# DA1469x register map
Vendor: Dialog; Series: DA1469x; File version: 1.2
CPU: CM33 r1p0, little endian, no MPU, FPU, 3 interrupt priority bits
Registers are 32-bit, read-write, reset 0x0 unless marked. A register's access mark holds for its fields unless they carry their own. Offsets are from the block's base; [hi:lo] are bit positions.

## RTC — RTC registers
Base 0x50000400
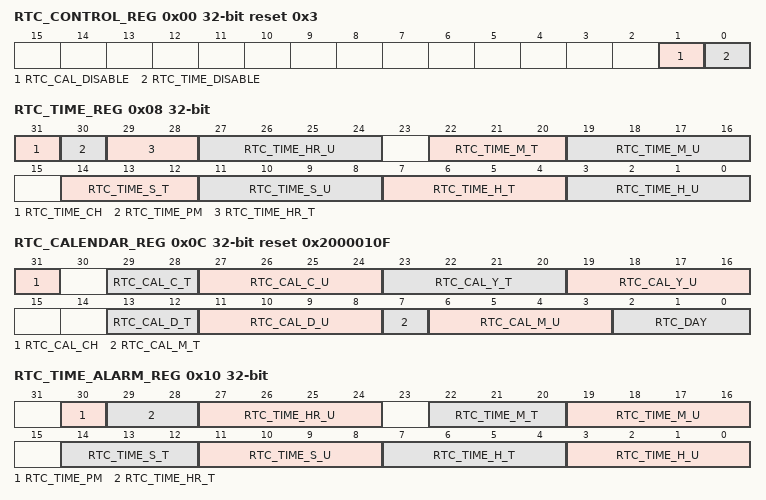
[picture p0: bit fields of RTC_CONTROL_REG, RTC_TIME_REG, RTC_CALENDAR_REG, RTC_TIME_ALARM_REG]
0x00 RTC_CONTROL_REG reset 0x3 — RTC Control Register
  [1] RTC_CAL_DISABLE — When this field is set high the RTC stops incrementing the calendar value.
  [0] RTC_TIME_DISABLE — When this field is set high the RTC stops incrementing the time value.
0x04 RTC_HOUR_MODE_REG — RTC Hour Mode Register
  [0] RTC_HMS — When this field is set high the RTC operates in 12 hour clock mode; otherwise, times are in 24 hour clock format.
0x08 RTC_TIME_REG (reset mask 0x7FFFFFFF) — RTC Time Register
  [31] RTC_TIME_CH — The value in this register has altered since last read. Read and clear.
  [30] RTC_TIME_PM — In 12 hour clock mode, indicates PM when set.
  [29:28] RTC_TIME_HR_T — Hours tens. Represented in BCD digit (0-2).
  [27:24] RTC_TIME_HR_U — Hours units. Represented in BCD digit (0-9).
  [22:20] RTC_TIME_M_T — Minutes tens. Represented in BCD digit (0-5).
  [19:16] RTC_TIME_M_U — Minutes units. Represented in BCD digit (0-9).
  [14:12] RTC_TIME_S_T — Seconds tens. Represented in BCD digit (0-9).
  [11:8] RTC_TIME_S_U — Seconds units. Represented in BCD digit (0-9).
  [7:4] RTC_TIME_H_T — Hundredths of a second tens. Represented in BCD digit (0-9).
  [3:0] RTC_TIME_H_U — Hundredths of a second units. Represented in BCD digit (0-9).
0x0C RTC_CALENDAR_REG reset 0x2000010F (reset mask 0x7FFFFFFF) — RTC Calendar Register
  [31] RTC_CAL_CH — The value in this register has altered since last read. Read and clear
  [29:28] RTC_CAL_C_T — Century tens. Represented in BCD digit (1-2).
  [27:24] RTC_CAL_C_U — Century units. Represented in BCD digit (0-9).
  [23:20] RTC_CAL_Y_T — Year tens. Represented in BCD digit (0-9).
  [19:16] RTC_CAL_Y_U — Year units. Represented in BCD digit (0-9).
  [13:12] RTC_CAL_D_T — Date tens. Represented in BCD digit (0-3).
  [11:8] RTC_CAL_D_U — Date units. Represented in BCD digit (0-9).
  [7] RTC_CAL_M_T — Month tens. Represented in BCD digit (0-1).
  [6:3] RTC_CAL_M_U — Month units. Represented in BCD digit (0-9).
  [2:0] RTC_DAY — Day of the week (arbitrary) units. Represented in BCD digit (0-7).
0x10 RTC_TIME_ALARM_REG — RTC Time Alarm Register
  [30] RTC_TIME_PM — In 12 hour clock mode, indicates PM when set.
  [29:28] RTC_TIME_HR_T — Hours tens. Represented in BCD digit (0-2).
  [27:24] RTC_TIME_HR_U — Hours units. Represented in BCD digit (0-9).
  [22:20] RTC_TIME_M_T — Minutes tens. Represented in BCD digit (0-5).
  [19:16] RTC_TIME_M_U — Minutes units. Represented in BCD digit (0-9).
  [14:12] RTC_TIME_S_T — Seconds tens. Represented in BCD digit (0-9).
  [11:8] RTC_TIME_S_U — Seconds units. Represented in BCD digit (0-9).
  [7:4] RTC_TIME_H_T — Hundredths of a second tens. Represented in BCD digit (0-9).
  [3:0] RTC_TIME_H_U — Hundredths of a second units. Represented in BCD digit (0-9).
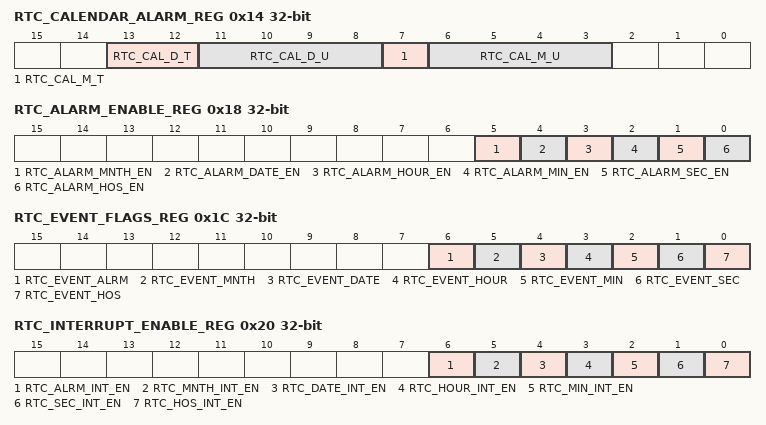
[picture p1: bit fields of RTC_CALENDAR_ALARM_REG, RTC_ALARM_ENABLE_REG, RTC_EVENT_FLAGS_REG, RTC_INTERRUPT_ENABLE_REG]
0x14 RTC_CALENDAR_ALARM_REG — RTC Calendar Alram Register
  [13:12] RTC_CAL_D_T — Date tens. Represented in BCD digit (0-3).
  [11:8] RTC_CAL_D_U — Date units. Represented in BCD digit (0-9).
  [7] RTC_CAL_M_T — Month tens. Represented in BCD digit (0-1).
  [6:3] RTC_CAL_M_U — Month units. Represented in BCD digit (0-9).
0x18 RTC_ALARM_ENABLE_REG — RTC Alarm Enable Register
  [5] RTC_ALARM_MNTH_EN — Alarm on month enable. Enable to trigger alarm when data specified in Calendar Alarm Register (M_T and M_U) has been reached.
  [4] RTC_ALARM_DATE_EN — Alarm on date enable. Enable to trigger alarm when data specified in Calendar Alarm Register (D_T and D_U) has been reached.
  [3] RTC_ALARM_HOUR_EN — Alarm on hour enable. Enable to trigger alarm when data specified in Time Alarm Register (PM, HR_T and HR_U) has been reached.
  [2] RTC_ALARM_MIN_EN — Alarm on minute enable. Enable to trigger alarm when data specified in Time Alarm Register (M_T and M_U) has been reached.
  [1] RTC_ALARM_SEC_EN — Alarm on second enable. Enable to trigger alarm when data specified in Time Alarm Register (S_T and S_U) has been reached.
  [0] RTC_ALARM_HOS_EN — Alarm on hundredths of a second enable. Enable to trigger alarm when data specified in Time Alarm Register (H_T and H_U) has been reached.
0x1C RTC_EVENT_FLAGS_REG — RTC Event Flags Register
  [6] RTC_EVENT_ALRM ro — Alarm event flag. Indicate that alarm event occurred since the last reset.
  [5] RTC_EVENT_MNTH ro — Month rolls over event flag. Indicate that month rolls over event occurred since the last reset.
  [4] RTC_EVENT_DATE ro — Date rolls over event flag. Indicate that date rolls over event occurred since the last reset.
  [3] RTC_EVENT_HOUR ro — Hour rolls over event flag. Indicate that hour rolls over event occurred since the last reset.
  [2] RTC_EVENT_MIN ro — Minute rolls over event flag. Indicate that minute rolls over event occurred since the last reset.
  [1] RTC_EVENT_SEC ro — Second rolls over event flag. Indicate that second rolls over event occurred since the last reset.
  [0] RTC_EVENT_HOS ro — Hundredths of a second event flag. Indicate that hundredths of a second rolls over event occurred since the last reset.
0x20 RTC_INTERRUPT_ENABLE_REG — RTC Interrupt Enable Register
  [6] RTC_ALRM_INT_EN wo — Interrupt on alarm enable. Enable to issue the interrupt when alarm event occurred.
  [5] RTC_MNTH_INT_EN wo — Interrupt on month enable. Enable to issue the interrupt when month event occurred.
  [4] RTC_DATE_INT_EN wo — Interrupt on date enable. Enable to issue the interrupt when date event occurred.
  [3] RTC_HOUR_INT_EN wo — Interrupt on hour enable. Enable to issue the interrupt when hour event occurred.
  [2] RTC_MIN_INT_EN wo — Interrupt on minute enable. Enable to issue the interrupt when minute event occurred.
  [1] RTC_SEC_INT_EN wo — Interrupt on second enable. Enable to issue the interrupt when second event occurred.
  [0] RTC_HOS_INT_EN wo — Interrupt on hundredths of a second enable. Enable to issue the interrupt when hundredths of a second event occurred.
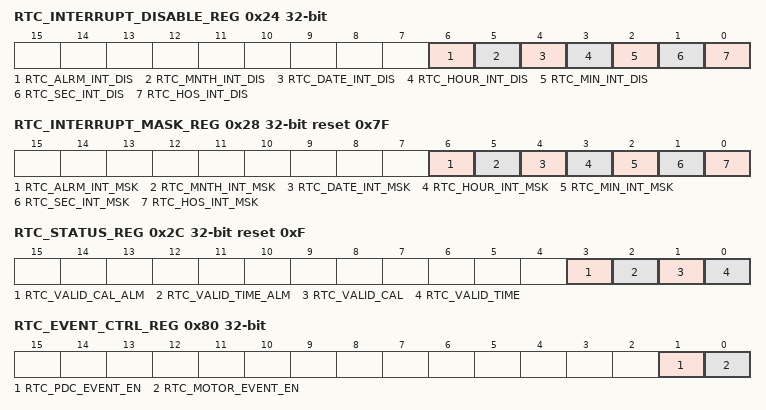
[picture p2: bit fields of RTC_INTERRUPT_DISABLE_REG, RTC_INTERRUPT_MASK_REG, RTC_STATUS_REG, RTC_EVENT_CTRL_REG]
0x24 RTC_INTERRUPT_DISABLE_REG — RTC Interrupt Disable Register
  [6] RTC_ALRM_INT_DIS wo — Interrupt on alarm disable. Disable to issue the interrupt when alarm event occurred.
  [5] RTC_MNTH_INT_DIS wo — Interrupt on month disable. Disable to issue the interrupt when month event occurred.
  [4] RTC_DATE_INT_DIS wo — Interrupt on date disable. Disable to issue the interrupt when date event occurred.
  [3] RTC_HOUR_INT_DIS wo — IInterrupt on hour disable. Disable to issue the interrupt when hour event occurred.
  [2] RTC_MIN_INT_DIS wo — Interrupt on minute disable. Disable to issue the interrupt when minute event occurred.
  [1] RTC_SEC_INT_DIS wo — Interrupt on second disable. Disable to issue the interrupt when second event occurred.
  [0] RTC_HOS_INT_DIS wo — Interrupt on hundredths of a second disable. Disable to issue the interrupt when hundredths of a second event occurred.
0x28 RTC_INTERRUPT_MASK_REG reset 0x7F — RTC Interrupt Mask Register
  [6] RTC_ALRM_INT_MSK ro — Mask alarm interrupt. It can be cleared (set) by setting corresponding bit (ALRM) in Interrupt Enable Register (Interrupt Disable Register).
  [5] RTC_MNTH_INT_MSK ro — IMask month interrupt. It can be cleared (set) by setting corresponding bit (MNTH) in Interrupt Enable Register (Interrupt Disable Register).
  [4] RTC_DATE_INT_MSK ro — Mask date interrupt. It can be cleared (set) by setting corresponding bit (DATE) in Interrupt Enable Register (Interrupt Disable Register).
  [3] RTC_HOUR_INT_MSK ro — IMask hour interrupt. It can be cleared (set) by setting corresponding bit (HOUR) in Interrupt Enable Register (Interrupt Disable Register).
  [2] RTC_MIN_INT_MSK ro — IMask minute interrupt. It can be cleared (set) by setting corresponding bit (MIN) in Interrupt Enable Register (Interrupt Disable Register).
  [1] RTC_SEC_INT_MSK ro — IMask second interrupt. It can be cleared (set) by setting corresponding bit (SEC) in Interrupt Enable Register (Interrupt Disable Register).
  [0] RTC_HOS_INT_MSK ro — Mask hundredths of a second interrupt. It can be cleared (set) by setting corresponding bit (HOS) in Interrupt Enable Register (Interrupt Disable Register).
0x2C RTC_STATUS_REG reset 0xF — RTC Status Register
  [3] RTC_VALID_CAL_ALM ro — Valid Calendar Alarm. If cleared then indicates that invalid entry occurred when writing to Calendar Alarm Register.
  [2] RTC_VALID_TIME_ALM ro — Valid Time Alarm. If cleared then indicates that invalid entry occurred when writing to Time Alarm Register.
  [1] RTC_VALID_CAL ro — Valid Calendar. If cleared then indicates that invalid entry occurred when writing to Calendar Register.
  [0] RTC_VALID_TIME ro — Valid Time. If cleared then indicates that invalid entry occurred when writing to Time Register.
0x30 RTC_KEEP_RTC_REG reset 0x1 — RTC Keep RTC Register
  [0] RTC_KEEP — Keep RTC. When high, the time and calendar registers and any other registers which directly affect or are affected by the time and calendar registers are NOT reset when software reset is applied. When low, the software reset will reset every register except the keep RTC and control registers.
0x80 RTC_EVENT_CTRL_REG — RTC Event Control Register
  [1] RTC_PDC_EVENT_EN — 0 = Event to PDC is disabled. No clear any pending event 1 = Even to PDC is enabled
  [0] RTC_MOTOR_EVENT_EN — 0 = Event to Motor is disabled 1 = Event to Motor is enabled
0x84 RTC_MOTOR_EVENT_PERIOD_REG — RTC Motor Event Period Register
  [11:0] RTC_MOTOR_EVENT_PERIOD — RTC wil send an event to motor (if RTC_MOTOR_EVENT_EN=1) every (RTC_MOTOR_EVENT_PERIOD+1)*10ms
0x88 RTC_PDC_EVENT_PERIOD_REG — RTC PDC Event Period Register
  [12:0] RTC_PDC_EVENT_PERIOD — RTC wil send an event to PDC (if RTC_PDC_EVENT_EN=1) every (RTC_PDC_EVENT_PERIOD+1)*10ms
0x8C RTC_PDC_EVENT_CLEAR_REG — RTC PDC Event Clear Register
  [0] PDC_EVENT_CLEAR ro — On read, PDC event is cleared
0x90 RTC_MOTOR_EVENT_CNT_REG — RTC Motor Event Counter Register
  [11:0] RTC_MOTOR_EVENT_CNT ro — It gives the current value of the Motor event counter (0 to RTC_MOTOR_EVENT_PERIOD)
0x94 RTC_PDC_EVENT_CNT_REG — RTC PDC Event Counter Register
  [12:0] RTC_PDC_EVENT_CNT ro — It gives the current value of the PDC event counter (0 to RTC_PDC_EVENT_PERIOD)
